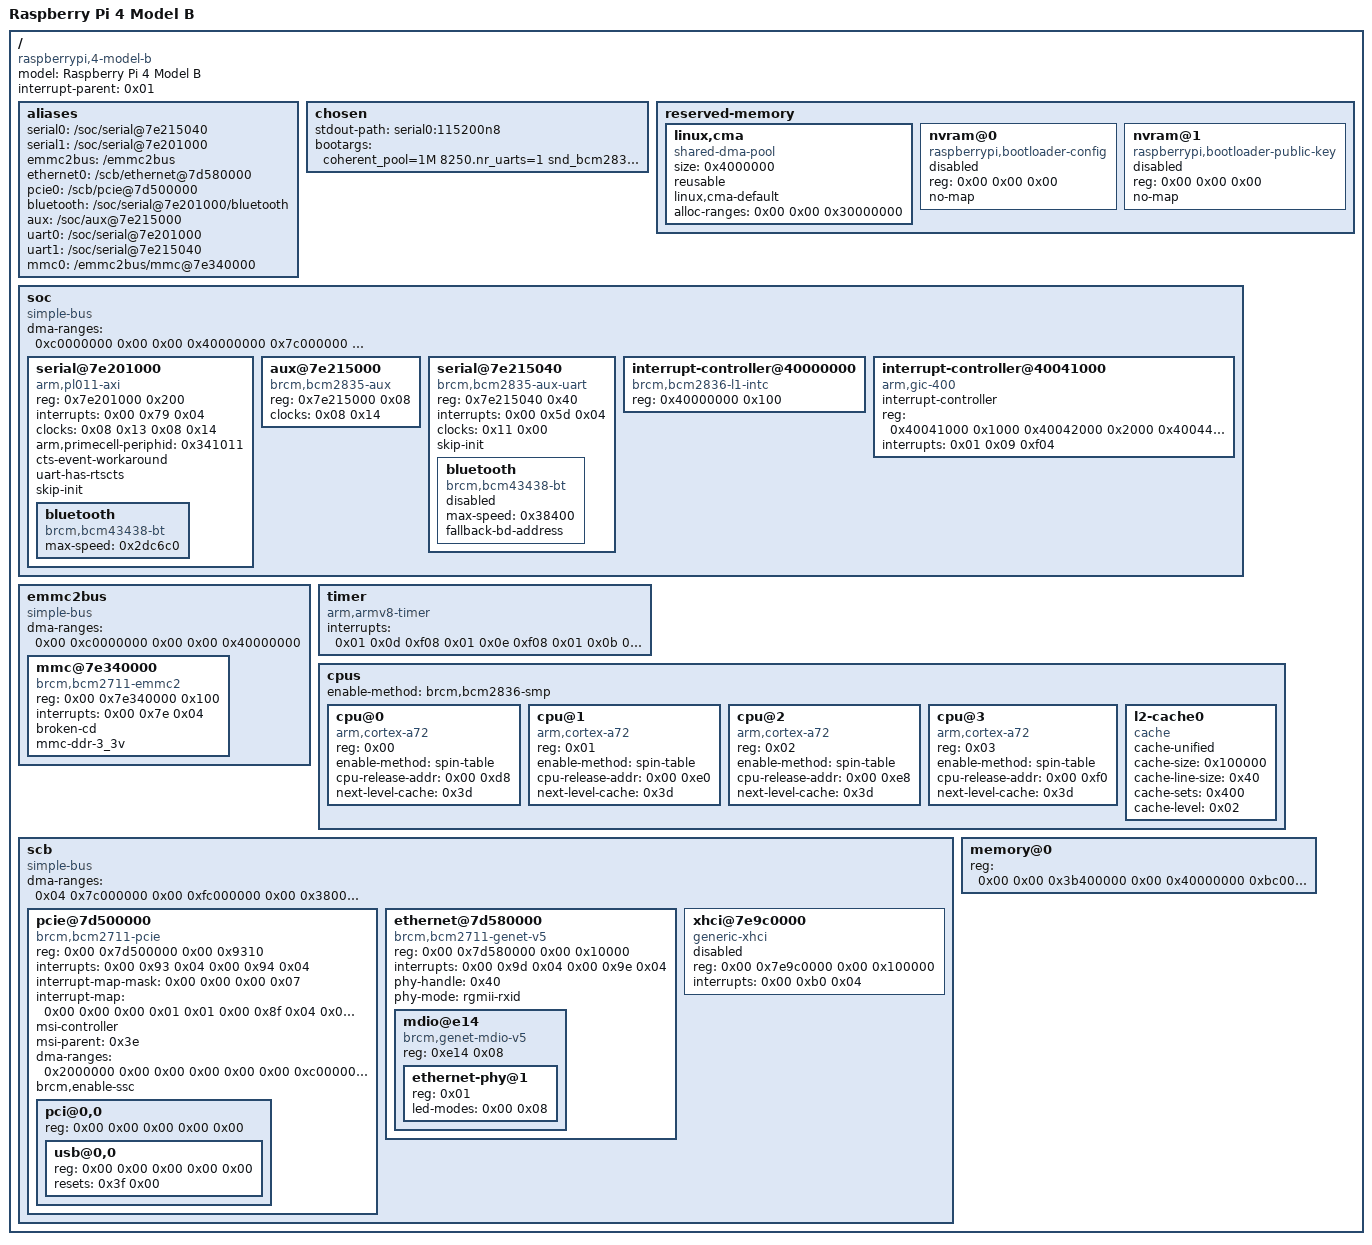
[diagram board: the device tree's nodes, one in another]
// Raspberry Pi 4 Model B, cut down from bcm2711-rpi-4-b.dtb in the Raspberry
// Pi firmware release 1.20260521 (nixpkgs raspberrypifw), decompiled with dtc
// 1.8.1. Kept: every node the kernel reads at boot and the buses above them,
// with values, order and phandles unchanged; dropped: pin control, clocks,
// display, audio and the rest. One node is not in the shipped blob:
// memory@0, which start4.elf writes before handing over; its value is what
// a 4 GB board reports and should be checked against the owner's board.

/dts-v1/;

/memreserve/	0x0000000000000000 0x0000000000001000;
/ {
	compatible = "raspberrypi,4-model-b", "brcm,bcm2711";
	model = "Raspberry Pi 4 Model B";
	#address-cells = <0x02>;
	#size-cells = <0x01>;
	interrupt-parent = <0x01>;

	aliases {
		serial0 = "/soc/serial@7e215040";
		serial1 = "/soc/serial@7e201000";
		emmc2bus = "/emmc2bus";
		ethernet0 = "/scb/ethernet@7d580000";
		pcie0 = "/scb/pcie@7d500000";
		bluetooth = "/soc/serial@7e201000/bluetooth";
		aux = "/soc/aux@7e215000";
		uart0 = "/soc/serial@7e201000";
		uart1 = "/soc/serial@7e215040";
		mmc0 = "/emmc2bus/mmc@7e340000";
		phandle = <0x4f>;
	};

	chosen {
		stdout-path = "serial0:115200n8";
		bootargs = "coherent_pool=1M 8250.nr_uarts=1 snd_bcm2835.enable_headphones=0 cgroup_disable=memory numa_policy=interleave nvme.max_host_mem_size_mb=32";
		phandle = <0x54>;
	};

	reserved-memory {
		#address-cells = <0x02>;
		#size-cells = <0x01>;
		ranges;
		phandle = <0x5c>;

		linux,cma {
			compatible = "shared-dma-pool";
			size = <0x4000000>;
			reusable;
			linux,cma-default;
			alloc-ranges = <0x00 0x00 0x30000000>;
			phandle = <0x5d>;
		};

		nvram@0 {
			compatible = "raspberrypi,bootloader-config", "nvmem-rmem";
			#address-cells = <0x01>;
			#size-cells = <0x01>;
			reg = <0x00 0x00 0x00>;
			no-map;
			status = "disabled";
			phandle = <0x5e>;
		};

		nvram@1 {
			compatible = "raspberrypi,bootloader-public-key", "nvmem-rmem";
			#address-cells = <0x01>;
			#size-cells = <0x01>;
			reg = <0x00 0x00 0x00>;
			no-map;
			status = "disabled";
			phandle = <0x5f>;
		};
	};

	soc {
		compatible = "simple-bus";
		#address-cells = <0x01>;
		#size-cells = <0x01>;
		ranges = <0x7e000000 0x00 0xfe000000 0x1800000 0x7c000000 0x00 0xfc000000 0x2000000 0x40000000 0x00 0xff800000 0x800000>;
		dma-ranges = <0xc0000000 0x00 0x00 0x40000000 0x7c000000 0x00 0xfc000000 0x3800000>;
		phandle = <0x63>;

		serial@7e201000 {
			compatible = "arm,pl011-axi", "arm,pl011", "arm,primecell";
			reg = <0x7e201000 0x200>;
			interrupts = <0x00 0x79 0x04>;
			clocks = <0x08 0x13 0x08 0x14>;
			clock-names = "uartclk", "apb_pclk";
			arm,primecell-periphid = <0x341011>;
			status = "okay";
			cts-event-workaround;
			uart-has-rtscts;
			skip-init;
			phandle = <0x43>;

			bluetooth {
				compatible = "brcm,bcm43438-bt";
				max-speed = <0x2dc6c0>;
				status = "okay";
				phandle = <0x41>;
			};
		};

		aux@7e215000 {
			compatible = "brcm,bcm2835-aux";
			#clock-cells = <0x01>;
			reg = <0x7e215000 0x08>;
			clocks = <0x08 0x14>;
			phandle = <0x11>;
		};

		serial@7e215040 {
			compatible = "brcm,bcm2835-aux-uart";
			reg = <0x7e215040 0x40>;
			interrupts = <0x00 0x5d 0x04>;
			clocks = <0x11 0x00>;
			status = "okay";
			skip-init;
			phandle = <0x44>;

			bluetooth {
				compatible = "brcm,bcm43438-bt";
				max-speed = <0x38400>;
				fallback-bd-address;
				status = "disabled";
				phandle = <0x42>;
			};
		};

		interrupt-controller@40000000 {
			compatible = "brcm,bcm2836-l1-intc";
			reg = <0x40000000 0x100>;
			phandle = <0xc6>;
		};

		interrupt-controller@40041000 {
			interrupt-controller;
			#interrupt-cells = <0x03>;
			compatible = "arm,gic-400";
			reg = <0x40041000 0x1000 0x40042000 0x2000 0x40044000 0x2000 0x40046000 0x2000>;
			interrupts = <0x01 0x09 0xf04>;
			phandle = <0x01>;
		};
	};

	emmc2bus {
		compatible = "simple-bus";
		#address-cells = <0x02>;
		#size-cells = <0x01>;
		ranges = <0x00 0x7e000000 0x00 0xfe000000 0x1800000>;
		dma-ranges = <0x00 0xc0000000 0x00 0x00 0x40000000>;
		phandle = <0xe6>;

		mmc@7e340000 {
			compatible = "brcm,bcm2711-emmc2";
			reg = <0x00 0x7e340000 0x100>;
			interrupts = <0x00 0x7e 0x04>;
			broken-cd;
			mmc-ddr-3_3v;
			status = "okay";
			phandle = <0x59>;
		};
	};

	timer {
		compatible = "arm,armv8-timer";
		interrupts = <0x01 0x0d 0xf08 0x01 0x0e 0xf08 0x01 0x0b 0xf08 0x01 0x0a 0xf08>;
	};

	cpus {
		#address-cells = <0x01>;
		#size-cells = <0x00>;
		enable-method = "brcm,bcm2836-smp";
		phandle = <0xe7>;

		cpu@0 {
			device_type = "cpu";
			compatible = "arm,cortex-a72";
			reg = <0x00>;
			enable-method = "spin-table";
			cpu-release-addr = <0x00 0xd8>;
			next-level-cache = <0x3d>;
			phandle = <0x39>;
		};

		cpu@1 {
			device_type = "cpu";
			compatible = "arm,cortex-a72";
			reg = <0x01>;
			enable-method = "spin-table";
			cpu-release-addr = <0x00 0xe0>;
			next-level-cache = <0x3d>;
			phandle = <0x3a>;
		};

		cpu@2 {
			device_type = "cpu";
			compatible = "arm,cortex-a72";
			reg = <0x02>;
			enable-method = "spin-table";
			cpu-release-addr = <0x00 0xe8>;
			next-level-cache = <0x3d>;
			phandle = <0x3b>;
		};

		cpu@3 {
			device_type = "cpu";
			compatible = "arm,cortex-a72";
			reg = <0x03>;
			enable-method = "spin-table";
			cpu-release-addr = <0x00 0xf0>;
			next-level-cache = <0x3d>;
			phandle = <0x3c>;
		};

		l2-cache0 {
			compatible = "cache";
			cache-unified;
			cache-size = <0x100000>;
			cache-line-size = <0x40>;
			cache-sets = <0x400>;
			cache-level = <0x02>;
			phandle = <0x3d>;
		};
	};

	scb {
		compatible = "simple-bus";
		#address-cells = <0x02>;
		#size-cells = <0x02>;
		ranges = <0x00 0x7c000000 0x00 0xfc000000 0x00 0x3800000 0x00 0x40000000 0x00 0xff800000 0x00 0x800000 0x06 0x00 0x06 0x00 0x00 0x40000000 0x00 0x00 0x00 0x00 0x00 0xfc000000>;
		dma-ranges = <0x04 0x7c000000 0x00 0xfc000000 0x00 0x3800000 0x00 0x00 0x00 0x00 0x04 0x00>;
		phandle = <0xe8>;

		pcie@7d500000 {
			compatible = "brcm,bcm2711-pcie";
			reg = <0x00 0x7d500000 0x00 0x9310>;
			device_type = "pci";
			#address-cells = <0x03>;
			#interrupt-cells = <0x01>;
			#size-cells = <0x02>;
			interrupts = <0x00 0x93 0x04 0x00 0x94 0x04>;
			interrupt-names = "pcie", "msi";
			interrupt-map-mask = <0x00 0x00 0x00 0x07>;
			interrupt-map = <0x00 0x00 0x00 0x01 0x01 0x00 0x8f 0x04 0x00 0x00 0x00 0x02 0x01 0x00 0x90 0x04 0x00 0x00 0x00 0x03 0x01 0x00 0x91 0x04 0x00 0x00 0x00 0x04 0x01 0x00 0x92 0x04>;
			msi-controller;
			msi-parent = <0x3e>;
			ranges = <0x2000000 0x00 0xc0000000 0x06 0x00 0x00 0x40000000>;
			dma-ranges = <0x2000000 0x00 0x00 0x00 0x00 0x00 0xc0000000>;
			brcm,enable-ssc;
			phandle = <0x3e>;

			pci@0,0 {
				device_type = "pci";
				#address-cells = <0x03>;
				#size-cells = <0x02>;
				ranges;
				reg = <0x00 0x00 0x00 0x00 0x00>;

				usb@0,0 {
					reg = <0x00 0x00 0x00 0x00 0x00>;
					resets = <0x3f 0x00>;
				};
			};
		};

		ethernet@7d580000 {
			compatible = "brcm,bcm2711-genet-v5";
			reg = <0x00 0x7d580000 0x00 0x10000>;
			#address-cells = <0x01>;
			#size-cells = <0x01>;
			interrupts = <0x00 0x9d 0x04 0x00 0x9e 0x04>;
			status = "okay";
			phy-handle = <0x40>;
			phy-mode = "rgmii-rxid";
			phandle = <0xe9>;

			mdio@e14 {
				compatible = "brcm,genet-mdio-v5";
				reg = <0xe14 0x08>;
				reg-names = "mdio";
				#address-cells = <0x01>;
				#size-cells = <0x00>;
				phandle = <0xea>;

				ethernet-phy@1 {
					reg = <0x01>;
					led-modes = <0x00 0x08>;
					phandle = <0x40>;
				};
			};
		};

		xhci@7e9c0000 {
			compatible = "generic-xhci";
			status = "disabled";
			reg = <0x00 0x7e9c0000 0x00 0x100000>;
			interrupts = <0x00 0xb0 0x04>;
			phandle = <0xec>;
		};
	};

	memory@0 {
		device_type = "memory";
		reg = <0x00 0x00 0x3b400000 0x00 0x40000000 0xbc000000>;
	};
};
